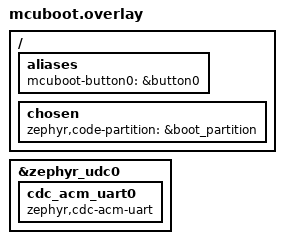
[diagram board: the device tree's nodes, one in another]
/* MCUboot overlay for VoLoRa custom board */

/ {
	aliases {
		mcuboot-button0 = &button0;
	};

	chosen {
		zephyr,code-partition = &boot_partition;
	};
};

/* USB CDC ACM for serial recovery */
&zephyr_udc0 {
	cdc_acm_uart0: cdc_acm_uart0 {
		compatible = "zephyr,cdc-acm-uart";
	};
};
